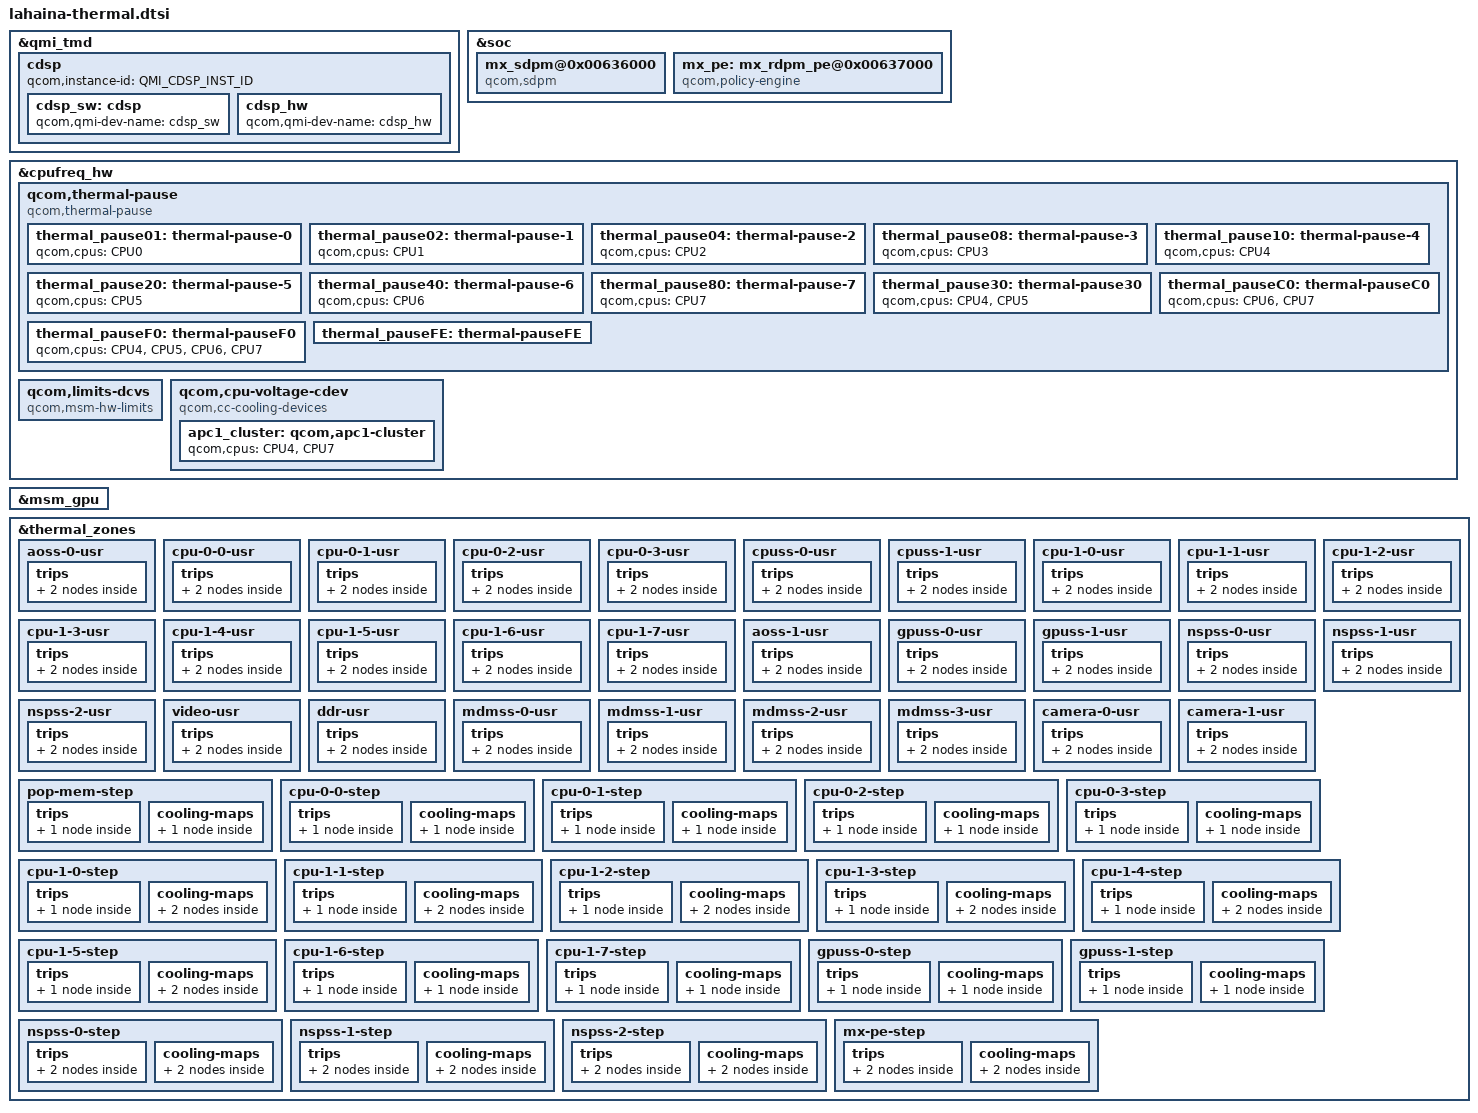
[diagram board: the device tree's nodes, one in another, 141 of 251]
#include <dt-bindings/thermal/thermal_qti.h>
#include "lahaina-thermal-modem.dtsi"

&qmi_tmd {
	cdsp {
		qcom,instance-id = <QMI_CDSP_INST_ID>;

		cdsp_sw: cdsp {
			qcom,qmi-dev-name = "cdsp_sw";
			#cooling-cells = <2>;
		};

		cdsp_hw: cdsp_hw {
			qcom,qmi-dev-name = "cdsp_hw";
			#cooling-cells = <2>;
		};
	};
};

&soc {
	mx_sdpm@0x00636000 {
		compatible = "qcom,sdpm";
		reg = <0x00636000 0x1000>;
		clock-names = "cam_cc_ipe", "video_cc_mvs0", "gcc_gp1";
		clocks = <&clock_camcc CAM_CC_IPE_0_CLK_SRC>,
			<&clock_videocc VIDEO_CC_MVS0_CLK_SRC>,
			<&clock_gcc GCC_GP1_CLK_SRC>;
		cam_cc_ipe-supply = <&cam_cc_ipe_0_gdsc>;
		video_cc_mvs0-supply = <&video_cc_mvs0_gdsc>;
		csr-id = <1 3 5>;
	};

	mx_pe: mx_rdpm_pe@0x00637000 {
		compatible = "qcom,policy-engine";
		#thermal-sensor-cells = <0>;
		reg = <0x00637000 0x1000>;
		interrupts = <GIC_SPI 237 IRQ_TYPE_LEVEL_HIGH>;
	};
};

&cpufreq_hw {
	qcom,thermal-pause {
		compatible = "qcom,thermal-pause";
		thermal_pause01: thermal-pause-0 {
			qcom,cpus = <&CPU0>;
			#cooling-cells = <2>;
		};

		thermal_pause02: thermal-pause-1 {
			qcom,cpus = <&CPU1>;
			#cooling-cells = <2>;
		};

		thermal_pause04: thermal-pause-2 {
			qcom,cpus = <&CPU2>;
			#cooling-cells = <2>;
		};

		thermal_pause08: thermal-pause-3 {
			qcom,cpus = <&CPU3>;
			#cooling-cells = <2>;
		};

		thermal_pause10: thermal-pause-4 {
			qcom,cpus = <&CPU4>;
			#cooling-cells = <2>;
		};

		thermal_pause20: thermal-pause-5 {
			qcom,cpus = <&CPU5>;
			#cooling-cells = <2>;
		};

		thermal_pause40: thermal-pause-6 {
			qcom,cpus = <&CPU6>;
			#cooling-cells = <2>;
		};

		thermal_pause80: thermal-pause-7 {
			qcom,cpus = <&CPU7>;
			#cooling-cells = <2>;
		};

		thermal_pause30: thermal-pause30 {
			qcom,cpus = <&CPU4 &CPU5>;
			#cooling-cells = <2>;
		};

		thermal_pauseC0: thermal-pauseC0 {
			qcom,cpus = <&CPU6 &CPU7>;
			#cooling-cells = <2>;
		};

		thermal_pauseF0: thermal-pauseF0 {
			qcom,cpus = <&CPU4 &CPU5 &CPU6 &CPU7>;
			#cooling-cells = <2>;
		};

		thermal_pauseFE: thermal-pauseFE {
			qcom,cpus =
				<&CPU1 &CPU2 &CPU3 &CPU4 &CPU5 &CPU6 &CPU7>;
			#cooling-cells = <2>;
		};
	};

	qcom,limits-dcvs {
		compatible = "qcom,msm-hw-limits";
		isens_vref_0p8-supply = <&pm8350_l5_ao>;
		isens-vref-0p8-settings = <880000 880000 30000>;
		isens_vref_1p8-supply = <&pm8350c_l1_ao>;
		isens-vref-1p8-settings = <1800000 1800000 20000>;
	};

	qcom,cpu-voltage-cdev {
		compatible = "qcom,cc-cooling-devices";
		apc1_cluster: qcom,apc1-cluster {
			qcom,cpus = <&CPU4 &CPU7>;
			#cooling-cells = <2>;
		};
	};
};

&msm_gpu {
	#cooling-cells = <2>;
};

&thermal_zones {
	aoss-0-usr {
		polling-delay-passive = <0>;
		polling-delay = <0>;
		thermal-governor = "user_space";
		thermal-sensors = <&tsens0 0>;
		trips {
			active-config0 {
				temperature = <125000>;
				hysteresis = <1000>;
				type = "passive";
			};

			reset-mon-cfg {
				temperature = <115000>;
				hysteresis = <5000>;
				type = "passive";
			};
		};
	};

	cpu-0-0-usr {
		polling-delay-passive = <0>;
		polling-delay = <0>;
		thermal-governor = "user_space";
		thermal-sensors = <&tsens0 1>;
		trips {
			active-config0 {
				temperature = <125000>;
				hysteresis = <1000>;
				type = "passive";
			};

			reset-mon-cfg {
				temperature = <115000>;
				hysteresis = <5000>;
				type = "passive";
			};
		};
	};

	cpu-0-1-usr {
		polling-delay-passive = <0>;
		polling-delay = <0>;
		thermal-governor = "user_space";
		thermal-sensors = <&tsens0 2>;
		trips {
			active-config0 {
				temperature = <125000>;
				hysteresis = <1000>;
				type = "passive";
			};

			reset-mon-cfg {
				temperature = <115000>;
				hysteresis = <5000>;
				type = "passive";
			};
		};
	};

	cpu-0-2-usr {
		polling-delay-passive = <0>;
		polling-delay = <0>;
		thermal-governor = "user_space";
		thermal-sensors = <&tsens0 3>;
		trips {
			active-config0 {
				temperature = <125000>;
				hysteresis = <1000>;
				type = "passive";
			};

			reset-mon-cfg {
				temperature = <115000>;
				hysteresis = <5000>;
				type = "passive";
			};
		};
	};

	cpu-0-3-usr {
		polling-delay-passive = <0>;
		polling-delay = <0>;
		thermal-governor = "user_space";
		thermal-sensors = <&tsens0 4>;
		trips {
			active-config0 {
				temperature = <125000>;
				hysteresis = <1000>;
				type = "passive";
			};

			reset-mon-cfg {
				temperature = <115000>;
				hysteresis = <5000>;
				type = "passive";
			};
		};
	};

	cpuss-0-usr {
		polling-delay-passive = <0>;
		polling-delay = <0>;
		thermal-governor = "user_space";
		thermal-sensors = <&tsens0 5>;
		trips {
			active-config0 {
				temperature = <125000>;
				hysteresis = <1000>;
				type = "passive";
			};

			reset-mon-cfg {
				temperature = <115000>;
				hysteresis = <5000>;
				type = "passive";
			};
		};
	};

	cpuss-1-usr {
		polling-delay-passive = <0>;
		polling-delay = <0>;
		thermal-governor = "user_space";
		thermal-sensors = <&tsens0 6>;
		trips {
			active-config0 {
				temperature = <125000>;
				hysteresis = <1000>;
				type = "passive";
			};

			reset-mon-cfg {
				temperature = <115000>;
				hysteresis = <5000>;
				type = "passive";
			};
		};
	};

	cpu-1-0-usr {
		polling-delay-passive = <0>;
		polling-delay = <0>;
		thermal-governor = "user_space";
		thermal-sensors = <&tsens0 7>;
		trips {
			active-config0 {
				temperature = <125000>;
				hysteresis = <1000>;
				type = "passive";
			};

			reset-mon-cfg {
				temperature = <115000>;
				hysteresis = <5000>;
				type = "passive";
			};
		};
	};

	cpu-1-1-usr {
		polling-delay-passive = <0>;
		polling-delay = <0>;
		thermal-governor = "user_space";
		thermal-sensors = <&tsens0 8>;
		trips {
			active-config0 {
				temperature = <125000>;
				hysteresis = <1000>;
				type = "passive";
			};

			reset-mon-cfg {
				temperature = <115000>;
				hysteresis = <5000>;
				type = "passive";
			};
		};
	};

	cpu-1-2-usr {
		polling-delay-passive = <0>;
		polling-delay = <0>;
		thermal-governor = "user_space";
		thermal-sensors = <&tsens0 9>;
		trips {
			active-config0 {
				temperature = <125000>;
				hysteresis = <1000>;
				type = "passive";
			};

			reset-mon-cfg {
				temperature = <115000>;
				hysteresis = <5000>;
				type = "passive";
			};
		};
	};

	cpu-1-3-usr {
		polling-delay-passive = <0>;
		polling-delay = <0>;
		thermal-governor = "user_space";
		thermal-sensors = <&tsens0 10>;
		trips {
			active-config0 {
				temperature = <125000>;
				hysteresis = <1000>;
				type = "passive";
			};

			reset-mon-cfg {
				temperature = <115000>;
				hysteresis = <5000>;
				type = "passive";
			};
		};
	};

	cpu-1-4-usr {
		polling-delay-passive = <0>;
		polling-delay = <0>;
		thermal-governor = "user_space";
		thermal-sensors = <&tsens0 11>;
		trips {
			active-config0 {
				temperature = <125000>;
				hysteresis = <1000>;
				type = "passive";
			};

			reset-mon-cfg {
				temperature = <115000>;
				hysteresis = <5000>;
				type = "passive";
			};
		};
	};

	cpu-1-5-usr {
		polling-delay-passive = <0>;
		polling-delay = <0>;
		thermal-governor = "user_space";
		thermal-sensors = <&tsens0 12>;
		trips {
			active-config0 {
				temperature = <125000>;
				hysteresis = <1000>;
				type = "passive";
			};

			reset-mon-cfg {
				temperature = <115000>;
				hysteresis = <5000>;
				type = "passive";
			};
		};
	};

	cpu-1-6-usr {
		polling-delay-passive = <0>;
		polling-delay = <0>;
		thermal-governor = "user_space";
		thermal-sensors = <&tsens0 13>;
		trips {
			active-config0 {
				temperature = <125000>;
				hysteresis = <1000>;
				type = "passive";
			};

			reset-mon-cfg {
				temperature = <115000>;
				hysteresis = <5000>;
				type = "passive";
			};
		};
	};

	cpu-1-7-usr {
		polling-delay-passive = <0>;
		polling-delay = <0>;
		thermal-governor = "user_space";
		thermal-sensors = <&tsens0 14>;
		trips {
			active-config0 {
				temperature = <125000>;
				hysteresis = <1000>;
				type = "passive";
			};

			reset-mon-cfg {
				temperature = <115000>;
				hysteresis = <5000>;
				type = "passive";
			};
		};
	};

	aoss-1-usr {
		polling-delay-passive = <0>;
		polling-delay = <0>;
		thermal-governor = "user_space";
		thermal-sensors = <&tsens1 0>;
		trips {
			active-config0 {
				temperature = <125000>;
				hysteresis = <1000>;
				type = "passive";
			};

			reset-mon-cfg {
				temperature = <115000>;
				hysteresis = <5000>;
				type = "passive";
			};
		};
	};

	gpuss-0-usr {
		polling-delay-passive = <0>;
		polling-delay = <0>;
		thermal-governor = "user_space";
		thermal-sensors = <&tsens1 1>;
		trips {
			active-config0 {
				temperature = <125000>;
				hysteresis = <1000>;
				type = "passive";
			};

			reset-mon-cfg {
				temperature = <115000>;
				hysteresis = <5000>;
				type = "passive";
			};
		};
	};

	gpuss-1-usr {
		polling-delay-passive = <0>;
		polling-delay = <0>;
		thermal-governor = "user_space";
		thermal-sensors = <&tsens1 2>;
		trips {
			active-config0 {
				temperature = <125000>;
				hysteresis = <1000>;
				type = "passive";
			};

			reset-mon-cfg {
				temperature = <115000>;
				hysteresis = <5000>;
				type = "passive";
			};
		};
	};

	nspss-0-usr {
		polling-delay-passive = <0>;
		polling-delay = <0>;
		thermal-governor = "user_space";
		thermal-sensors = <&tsens1 3>;
		trips {
			active-config0 {
				temperature = <125000>;
				hysteresis = <1000>;
				type = "passive";
			};

			reset-mon-cfg {
				temperature = <115000>;
				hysteresis = <5000>;
				type = "passive";
			};
		};
	};

	nspss-1-usr {
		polling-delay-passive = <0>;
		polling-delay = <0>;
		thermal-governor = "user_space";
		thermal-sensors = <&tsens1 4>;
		trips {
			active-config0 {
				temperature = <125000>;
				hysteresis = <1000>;
				type = "passive";
			};

			reset-mon-cfg {
				temperature = <115000>;
				hysteresis = <5000>;
				type = "passive";
			};
		};
	};

	nspss-2-usr {
		polling-delay-passive = <0>;
		polling-delay = <0>;
		thermal-governor = "user_space";
		thermal-sensors = <&tsens1 5>;
		trips {
			active-config0 {
				temperature = <125000>;
				hysteresis = <1000>;
				type = "passive";
			};

			reset-mon-cfg {
				temperature = <115000>;
				hysteresis = <5000>;
				type = "passive";
			};
		};
	};

	video-usr {
		polling-delay-passive = <0>;
		polling-delay = <0>;
		thermal-governor = "user_space";
		thermal-sensors = <&tsens1 6>;
		trips {
			active-config0 {
				temperature = <125000>;
				hysteresis = <1000>;
				type = "passive";
			};

			reset-mon-cfg {
				temperature = <115000>;
				hysteresis = <5000>;
				type = "passive";
			};
		};
	};

	ddr-usr {
		polling-delay-passive = <0>;
		polling-delay = <0>;
		thermal-governor = "user_space";
		thermal-sensors = <&tsens1 7>;
		trips {
			active-config0 {
				temperature = <125000>;
				hysteresis = <1000>;
				type = "passive";
			};

			reset-mon-cfg {
				temperature = <115000>;
				hysteresis = <5000>;
				type = "passive";
			};
		};
	};

	mdmss-0-usr {
		polling-delay-passive = <0>;
		polling-delay = <0>;
		thermal-governor = "user_space";
		thermal-sensors = <&tsens1 8>;
		trips {
			active-config0 {
				temperature = <125000>;
				hysteresis = <1000>;
				type = "passive";
			};

			reset-mon-cfg {
				temperature = <115000>;
				hysteresis = <5000>;
				type = "passive";
			};
		};
	};

	mdmss-1-usr {
		polling-delay-passive = <0>;
		polling-delay = <0>;
		thermal-governor = "user_space";
		thermal-sensors = <&tsens1 9>;
		trips {
			active-config0 {
				temperature = <125000>;
				hysteresis = <1000>;
				type = "passive";
			};

			reset-mon-cfg {
				temperature = <115000>;
				hysteresis = <5000>;
				type = "passive";
			};
		};
	};

	mdmss-2-usr {
		polling-delay-passive = <0>;
		polling-delay = <0>;
		thermal-governor = "user_space";
		thermal-sensors = <&tsens1 10>;
		trips {
			active-config0 {
				temperature = <125000>;
				hysteresis = <1000>;
				type = "passive";
			};

			reset-mon-cfg {
				temperature = <115000>;
				hysteresis = <5000>;
				type = "passive";
			};
		};
	};

	mdmss-3-usr {
		polling-delay-passive = <0>;
		polling-delay = <0>;
		thermal-governor = "user_space";
		thermal-sensors = <&tsens1 11>;
		trips {
			active-config0 {
				temperature = <125000>;
				hysteresis = <1000>;
				type = "passive";
			};

			reset-mon-cfg {
				temperature = <115000>;
				hysteresis = <5000>;
				type = "passive";
			};
		};
	};

	camera-0-usr {
		polling-delay-passive = <0>;
		polling-delay = <0>;
		thermal-governor = "user_space";
		thermal-sensors = <&tsens1 12>;
		trips {
			active-config0 {
				temperature = <125000>;
				hysteresis = <1000>;
				type = "passive";
			};

			reset-mon-cfg {
				temperature = <115000>;
				hysteresis = <5000>;
				type = "passive";
			};
		};
	};

	camera-1-usr {
		polling-delay-passive = <0>;
		polling-delay = <0>;
		thermal-governor = "user_space";
		thermal-sensors = <&tsens1 13>;
		trips {
			active-config0 {
				temperature = <125000>;
				hysteresis = <1000>;
				type = "passive";
			};

			reset-mon-cfg {
				temperature = <115000>;
				hysteresis = <5000>;
				type = "passive";
			};
		};
	};

	pop-mem-step {
		polling-delay-passive = <10>;
		polling-delay = <0>;
		thermal-sensors = <&tsens1 7>;
		thermal-governor = "step_wise";
		trips {
			pop_trip: pop-trip {
				temperature = <95000>;
				hysteresis = <0>;
				type = "passive";
			};
		};

		cooling-maps {
			pop_cdev {
				trip = <&pop_trip>;
				cooling-device =
					<&apc1_cluster THERMAL_NO_LIMIT
						THERMAL_NO_LIMIT>;
			};
		};
	};

	cpu-0-0-step {
		polling-delay-passive = <0>;
		polling-delay = <0>;
		thermal-governor = "step_wise";
		thermal-sensors = <&tsens0 1>;
		trips {
			cpu00_config: cpu00-config {
				temperature = <110000>;
				hysteresis = <10000>;
				type = "passive";
			};
		};

		cooling-maps {
			cpu00_cdev {
				trip = <&cpu00_config>;
				cooling-device = <&thermal_pause01 1 1>;
			};
		};
	};

	cpu-0-1-step {
		polling-delay-passive = <0>;
		polling-delay = <0>;
		thermal-governor = "step_wise";
		thermal-sensors = <&tsens0 2>;
		trips {
			cpu01_config: cpu01-config {
				temperature = <110000>;
				hysteresis = <10000>;
				type = "passive";
			};
		};

		cooling-maps {
			cpu01_cdev {
				trip = <&cpu01_config>;
				cooling-device = <&thermal_pause02 1 1>;
			};
		};
	};

	cpu-0-2-step {
		polling-delay-passive = <0>;
		polling-delay = <0>;
		thermal-governor = "step_wise";
		thermal-sensors = <&tsens0 3>;
		trips {
			cpu02_config: cpu02-config {
				temperature = <110000>;
				hysteresis = <10000>;
				type = "passive";
			};
		};

		cooling-maps {
			cpu02_cdev {
				trip = <&cpu02_config>;
				cooling-device = <&thermal_pause04 1 1>;
			};
		};
	};

	cpu-0-3-step {
		polling-delay-passive = <0>;
		polling-delay = <0>;
		thermal-sensors = <&tsens0 4>;
		thermal-governor = "step_wise";
		trips {
			cpu03_config: cpu03-config {
				temperature = <110000>;
				hysteresis = <10000>;
				type = "passive";
			};
		};

		cooling-maps {
			cpu03_cdev {
				trip = <&cpu03_config>;
				cooling-device = <&thermal_pause08 1 1>;
			};
		};
	};

	cpu-1-0-step {
		polling-delay-passive = <0>;
		polling-delay = <0>;
		thermal-sensors = <&tsens0 7>;
		thermal-governor = "step_wise";
		trips {
			cpu10_config: cpu10-config {
				temperature = <110000>;
				hysteresis = <10000>;
				type = "passive";
			};
		};

		cooling-maps {
			cpu10_cdev {
				trip = <&cpu10_config>;
				cooling-device = <&thermal_pause10 1 1>;
			};

			cpu10_cdev1 {
				trip = <&cpu10_config>;
				cooling-device = <&CPU4 THERMAL_MAX_LIMIT
							THERMAL_MAX_LIMIT>;
			};
		};
	};

	cpu-1-1-step {
		polling-delay-passive = <0>;
		polling-delay = <0>;
		thermal-sensors = <&tsens0 8>;
		thermal-governor = "step_wise";
		trips {
			cpu11_config: cpu11-config {
				temperature = <110000>;
				hysteresis = <10000>;
				type = "passive";
			};
		};

		cooling-maps {
			cpu11_cdev {
				trip = <&cpu11_config>;
				cooling-device = <&thermal_pause10 1 1>;
			};

			cpu11_cdev1 {
				trip = <&cpu11_config>;
				cooling-device = <&CPU4 THERMAL_MAX_LIMIT
							THERMAL_MAX_LIMIT>;
			};
		};
	};

	cpu-1-2-step {
		polling-delay-passive = <0>;
		polling-delay = <0>;
		thermal-sensors = <&tsens0 9>;
		thermal-governor = "step_wise";
		trips {
			cpu12_config: cpu12-config {
				temperature = <110000>;
				hysteresis = <10000>;
				type = "passive";
			};
		};

		cooling-maps {
			cpu12_cdev {
				trip = <&cpu12_config>;
				cooling-device = <&thermal_pause20 1 1>;
			};

			cpu12_cdev1 {
				trip = <&cpu12_config>;
				cooling-device = <&CPU4 THERMAL_MAX_LIMIT
							THERMAL_MAX_LIMIT>;
			};
		};
	};

	cpu-1-3-step {
		polling-delay-passive = <0>;
		polling-delay = <0>;
		thermal-sensors = <&tsens0 10>;
		thermal-governor = "step_wise";
		trips {
			cpu13_config: cpu13-config {
				temperature = <110000>;
				hysteresis = <10000>;
				type = "passive";
			};
		};

		cooling-maps {
			cpu13_cdev {
				trip = <&cpu13_config>;
				cooling-device = <&thermal_pause20 1 1>;
			};

			cpu13_cdev1 {
				trip = <&cpu13_config>;
				cooling-device = <&CPU4 THERMAL_MAX_LIMIT
							THERMAL_MAX_LIMIT>;
			};
		};
	};

	cpu-1-4-step {
		polling-delay-passive = <0>;
		polling-delay = <0>;
		thermal-sensors = <&tsens0 11>;
		thermal-governor = "step_wise";
		trips {
			cpu14_config: cpu14-config {
				temperature = <110000>;
				hysteresis = <10000>;
				type = "passive";
			};
		};

		cooling-maps {
			cpu14_cdev {
				trip = <&cpu14_config>;
				cooling-device = <&thermal_pause40 1 1>;
			};

			cpu14_cdev1 {
				trip = <&cpu14_config>;
				cooling-device = <&CPU4 THERMAL_MAX_LIMIT
							THERMAL_MAX_LIMIT>;
			};
		};
	};

	cpu-1-5-step {
		polling-delay-passive = <0>;
		polling-delay = <0>;
		thermal-sensors = <&tsens0 12>;
		thermal-governor = "step_wise";
		trips {
			cpu15_config: cpu15-config {
				temperature = <110000>;
				hysteresis = <10000>;
				type = "passive";
			};
		};

		cooling-maps {
			cpu15_cdev {
				trip = <&cpu15_config>;
				cooling-device = <&thermal_pause40 1 1>;
			};

			cpu15_cdev1 {
				trip = <&cpu15_config>;
				cooling-device = <&CPU4 THERMAL_MAX_LIMIT
							THERMAL_MAX_LIMIT>;
			};
		};
	};

	cpu-1-6-step {
		polling-delay-passive = <0>;
		polling-delay = <0>;
		thermal-sensors = <&tsens0 13>;
		thermal-governor = "step_wise";
		trips {
			cpu16_config: cpu16-config {
				temperature = <110000>;
				hysteresis = <10000>;
				type = "passive";
			};
		};

		cooling-maps {
			cpu16_cdev {
				trip = <&cpu16_config>;
				cooling-device = <&thermal_pause80 1 1>;
			};
		};
	};

	cpu-1-7-step {
		polling-delay-passive = <0>;
		polling-delay = <0>;
		thermal-sensors = <&tsens0 14>;
		thermal-governor = "step_wise";
		trips {
			cpu17_config: cpu17-config {
				temperature = <110000>;
				hysteresis = <10000>;
				type = "passive";
			};
		};

		cooling-maps {
			cpu17_cdev {
				trip = <&cpu17_config>;
				cooling-device = <&thermal_pause80 1 1>;
			};
		};
	};

	gpuss-0-step {
		polling-delay-passive = <10>;
		polling-delay = <0>;
		thermal-governor = "step_wise";
		thermal-sensors = <&tsens1 1>;
		trips {
			gpuss0_config: active-config0 {
				temperature = <95000>;
				hysteresis = <0>;
				type = "passive";
			};
		};

		cooling-maps {
			gpu_cdev {
				trip = <&gpuss0_config>;
				cooling-device = <&msm_gpu THERMAL_NO_LIMIT
							THERMAL_NO_LIMIT>;
			};
		};
	};

	gpuss-1-step {
		polling-delay-passive = <10>;
		polling-delay = <0>;
		thermal-governor = "step_wise";
		thermal-sensors = <&tsens1 2>;
		trips {
			gpuss1_config: active-config0 {
				temperature = <95000>;
				hysteresis = <0>;
				type = "passive";
			};
		};

		cooling-maps {
			gpu_cdev {
				trip = <&gpuss1_config>;
				cooling-device = <&msm_gpu THERMAL_NO_LIMIT
							THERMAL_NO_LIMIT>;
			};
		};
	};

	nspss-0-step {
		polling-delay-passive = <10>;
		polling-delay = <0>;
		thermal-governor = "step_wise";
		thermal-sensors = <&tsens1 3>;
		trips {
			nspss0_config: active-config0 {
				temperature = <95000>;
				hysteresis = <0>;
				type = "passive";
			};

			nspss0_config1: active-config1 {
				temperature = <105000>;
				hysteresis = <10000>;
				type = "passive";
			};
		};

		cooling-maps {
			nsp_cdev {
				trip = <&nspss0_config>;
				cooling-device = <&cdsp_sw THERMAL_NO_LIMIT
							THERMAL_NO_LIMIT>;
			};

			nsp_cdev1 {
				trip = <&nspss0_config1>;
				cooling-device = <&cdsp_sw THERMAL_MAX_LIMIT
							THERMAL_MAX_LIMIT>;
			};
		};
	};

	nspss-1-step {
		polling-delay-passive = <10>;
		polling-delay = <0>;
		thermal-governor = "step_wise";
		thermal-sensors = <&tsens1 4>;
		trips {
			nspss1_config: active-config0 {
				temperature = <95000>;
				hysteresis = <0>;
				type = "passive";
			};

			nspss1_config1: active-config1 {
				temperature = <105000>;
				hysteresis = <10000>;
				type = "passive";
			};
		};

		cooling-maps {
			nsp_cdev {
				trip = <&nspss1_config>;
				cooling-device = <&cdsp_sw THERMAL_NO_LIMIT
							THERMAL_NO_LIMIT>;
			};

			nsp_cdev1 {
				trip = <&nspss1_config1>;
				cooling-device = <&cdsp_sw THERMAL_MAX_LIMIT
							THERMAL_MAX_LIMIT>;
			};
		};
	};

	nspss-2-step {
		polling-delay-passive = <10>;
		polling-delay = <0>;
		thermal-governor = "step_wise";
		thermal-sensors = <&tsens1 5>;
		trips {
			nspss2_config: active-config0 {
				temperature = <95000>;
				hysteresis = <0>;
				type = "passive";
			};

			nspss2_config1: active-config1 {
				temperature = <105000>;
				hysteresis = <10000>;
				type = "passive";
			};
		};

		cooling-maps {
			nsp_cdev {
				trip = <&nspss2_config>;
				cooling-device = <&cdsp_sw THERMAL_NO_LIMIT
							THERMAL_NO_LIMIT>;
			};

			nsp_cdev1 {
				trip = <&nspss2_config1>;
				cooling-device = <&cdsp_sw THERMAL_MAX_LIMIT
							THERMAL_MAX_LIMIT>;
			};
		};
	};

	mx-pe-step {
		polling-delay-passive = <0>;
		polling-delay = <0>;
		thermal-sensors = <&mx_pe>;
		thermal-governor = "step_wise";
		trips {
			mx_pe_config1: mx-pe-config1 {
				temperature = <1>;
				hysteresis = <1>;
				type = "passive";
			};

			mx_pe_config2: mx-pe-config2 {
				temperature = <2>;
				hysteresis = <1>;
				type = "passive";
			};
		};

		cooling-maps {
			mx_pe_cdev_1 {
				trip = <&mx_pe_config1>;
				cooling-device = <&cdsp_sw 1 1>;
			};

			mx_pe_cdev_2 {
				trip = <&mx_pe_config2>;
				cooling-device = <&msm_gpu 1 1>;
			};
		};
	};
};

